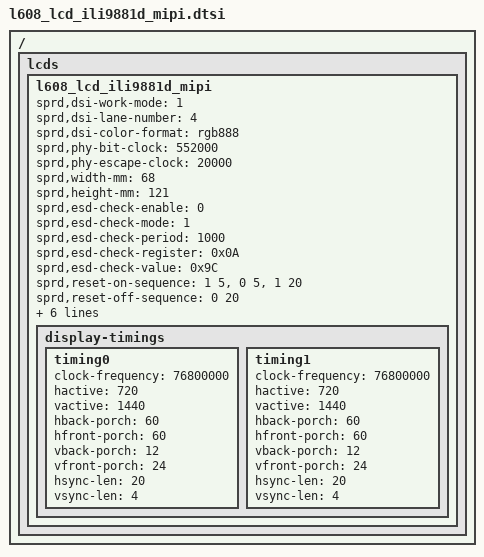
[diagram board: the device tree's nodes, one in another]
/ { lcds {
	l608_lcd_ili9881d_mipi: l608_lcd_ili9881d_mipi {

	
		sprd,dsi-work-mode = <1>; /* video burst mode*/
		sprd,dsi-lane-number = <4>;
		sprd,dsi-color-format = "rgb888";

		sprd,phy-bit-clock = <552000>;	/* kbps */
		sprd,phy-escape-clock = <20000>;/* kHz */

		sprd,width-mm = <68>;
		sprd,height-mm = <121>;

		sprd,esd-check-enable = <0>;
		sprd,esd-check-mode = <1>; //te
		sprd,esd-check-period = <1000>;
		sprd,esd-check-register = <0x0A>;
		sprd,esd-check-value = <0x9C>;

		sprd,reset-on-sequence = <1 5>, <0 5>, <1 20>;
		sprd,reset-off-sequence = <0 20>;
		sprd,initial-command = [
39 00 00 04 FF 98 81 03
//GIP_1
23 00 00 02 01 00 
23 00 00 02 02 00 
23 00 00 02 03 73 
23 00 00 02 04 73 
23 00 00 02 05 00 
23 00 00 02 06 06 
23 00 00 02 07 02 
23 00 00 02 08 00 
23 00 00 02 09 01 
23 00 00 02 0A 01 
23 00 00 02 0B 01 
23 00 00 02 0C 01 
23 00 00 02 0D 01 
23 00 00 02 0E 01 
23 00 00 02 0F 00 
23 00 00 02 10 00 
23 00 00 02 11 00 
23 00 00 02 12 00 
23 00 00 02 13 01 
23 00 00 02 14 00 
23 00 00 02 15 08 
23 00 00 02 16 08 
23 00 00 02 17 00 
23 00 00 02 18 08 
23 00 00 02 19 00 
23 00 00 02 1A 00 
23 00 00 02 1B 00 
23 00 00 02 1C 00 
23 00 00 02 1D 00 
23 00 00 02 1E C0 
23 00 00 02 1F 80 
23 00 00 02 20 03 
23 00 00 02 21 04 
23 00 00 02 22 00 
23 00 00 02 23 00 
23 00 00 02 24 00 
23 00 00 02 25 00 
23 00 00 02 26 00 
23 00 00 02 27 00 
23 00 00 02 28 33 
23 00 00 02 29 02 
23 00 00 02 2A 00 
23 00 00 02 2B 00 
23 00 00 02 2C 00 
23 00 00 02 2D 00 
23 00 00 02 2E 00 
23 00 00 02 2F 00 
23 00 00 02 30 00 
23 00 00 02 31 00 
23 00 00 02 32 00 
23 00 00 02 33 00 
23 00 00 02 34 03 
23 00 00 02 35 00 
23 00 00 02 36 03 
23 00 00 02 37 00 
23 00 00 02 38 00 
23 00 00 02 39 38 
23 00 00 02 3A 00 
23 00 00 02 3B 40 
23 00 00 02 3C 00 
23 00 00 02 3D 00 
23 00 00 02 3E 00 
23 00 00 02 3F 00 
23 00 00 02 40 38 
23 00 00 02 41 38 
23 00 00 02 42 00 
23 00 00 02 43 00 
23 00 00 02 44 3F 
23 00 00 02 45 20 
23 00 00 02 46 00 

//GIP_2
23 00 00 02 50 01 
23 00 00 02 51 23 
23 00 00 02 52 45 
23 00 00 02 53 67 
23 00 00 02 54 89 
23 00 00 02 55 ab 
23 00 00 02 56 01 
23 00 00 02 57 23 
23 00 00 02 58 45 
23 00 00 02 59 67 
23 00 00 02 5A 89 
23 00 00 02 5B ab 
23 00 00 02 5C cd 
23 00 00 02 5D ef 

//GIP_3
23 00 00 02 5E 10 
23 00 00 02 5F 09   
23 00 00 02 60 08 
23 00 00 02 61 0F 
23 00 00 02 62 0E 
23 00 00 02 63 0D 
23 00 00 02 64 0C 
23 00 00 02 65 02 
23 00 00 02 66 02 
23 00 00 02 67 02 
23 00 00 02 68 02 
23 00 00 02 69 02 
23 00 00 02 6A 02 
23 00 00 02 6B 02 
23 00 00 02 6C 02 
23 00 00 02 6D 02   
23 00 00 02 6E 02 
23 00 00 02 6F 02 
23 00 00 02 70 02 
23 00 00 02 71 06 
23 00 00 02 72 07 
23 00 00 02 73 02 
23 00 00 02 74 02 

23 00 00 02 75 06   
23 00 00 02 76 07   
23 00 00 02 77 0E 
23 00 00 02 78 0F 
23 00 00 02 79 0C 
23 00 00 02 7A 0D 
23 00 00 02 7B 02 
23 00 00 02 7C 02 
23 00 00 02 7D 02 
23 00 00 02 7E 02 
23 00 00 02 7F 02 
23 00 00 02 80 02 
23 00 00 02 81 02 
23 00 00 02 82 02 
23 00 00 02 83 02 
23 00 00 02 84 02   
23 00 00 02 85 02 
23 00 00 02 86 02 
23 00 00 02 87 09 
23 00 00 02 88 08 
23 00 00 02 89 02 
23 00 00 02 8A 02 
39 00 00 04 FF 98 81 04 
23 00 00 02 6D 08 
23 00 00 02 6F 05 
23 00 00 02 70 00    
23 00 00 02 71 00 
23 00 00 02 66 FE 
23 00 00 02 82 12    
23 00 00 02 84 0F 
23 00 00 02 85 12 
23 00 00 02 32 AC 
23 00 00 02 8C 80 
23 00 00 02 3C F5  
23 00 00 02 3A 24 
23 00 00 02 B5 07 
23 00 00 02 31 45 
23 00 00 02 88 33 
23 00 00 02 89 BA 
39 00 00 04 FF 98 81 01 
23 00 00 02 22 0A 
23 00 00 02 31 00 
23 00 00 02 41 24 
23 00 00 02 53 2F 
23 00 00 02 55 2F 
23 00 00 02 50 61 
23 00 00 02 51 61 
23 00 00 02 60 20  
23 00 00 02 61 00  
23 00 00 02 62 0D 
23 00 00 02 63 00  
23 00 00 02 2E F0   
23 00 00 02 2F 00 
23 00 00 02 A0 03 
23 00 00 02 A1 1B 
23 00 00 02 A2 2C 
23 00 00 02 A3 16 
23 00 00 02 A4 1C 
23 00 00 02 A5 31 
23 00 00 02 A6 25 
23 00 00 02 A7 24 
23 00 00 02 A8 9F 
23 00 00 02 A9 1C 
23 00 00 02 AA 27 
23 00 00 02 AB 81 
23 00 00 02 AC 1B   
23 00 00 02 AD 1B 
23 00 00 02 AE 51 
23 00 00 02 AF 26 
23 00 00 02 B0 2A 
23 00 00 02 B1 4F 
23 00 00 02 B2 5C 
23 00 00 02 B3 2E 
23 00 00 02 C0 03 
23 00 00 02 C1 1B 
23 00 00 02 C2 2C 
23 00 00 02 C3 16 
23 00 00 02 C4 1C 
23 00 00 02 C5 31 
23 00 00 02 C6 25 
23 00 00 02 C7 24 
23 00 00 02 C8 9F 
23 00 00 02 C9 1C 
23 00 00 02 CA 27 
23 00 00 02 CB 81 
23 00 00 02 CC 1B   
23 00 00 02 CD 1B 
23 00 00 02 CE 51 
23 00 00 02 CF 26 
23 00 00 02 D0 2A 
23 00 00 02 D1 4F 
23 00 00 02 D2 5C 
23 00 00 02 D3 2E 
39 00 00 04 FF 98 81 00 
23 00 00 02 35 00 
23 00 00 02 11 00 
23 78 00 02 11 00 
23 14 00 02 29 00 

			];
		sprd,sleep-in-command = [
	        //23 00 00 02 26 03
			13 0A 00 01 28
			13 78 00 01 10

			];
		sprd,sleep-out-command = [
			13 78 00 01 11
			13 64 00 01 29
			];
		display-timings {
			timing0 {
			clock-frequency = <76800000>;
			hactive = <720>;
			vactive = <1440>;
			hback-porch = <60>;
			hfront-porch = <60>;
			vback-porch = <12>;
			vfront-porch = <24>;
			hsync-len = <20>;
			vsync-len = <4>;
			};
			timing1 {
			clock-frequency = <76800000>;
			hactive = <720>;
			vactive = <1440>;
			hback-porch = <60>;
			hfront-porch = <60>;
			vback-porch = <12>;
			vfront-porch = <24>;
			hsync-len = <20>;
			vsync-len = <4>;
			};
		};
	};
};};

